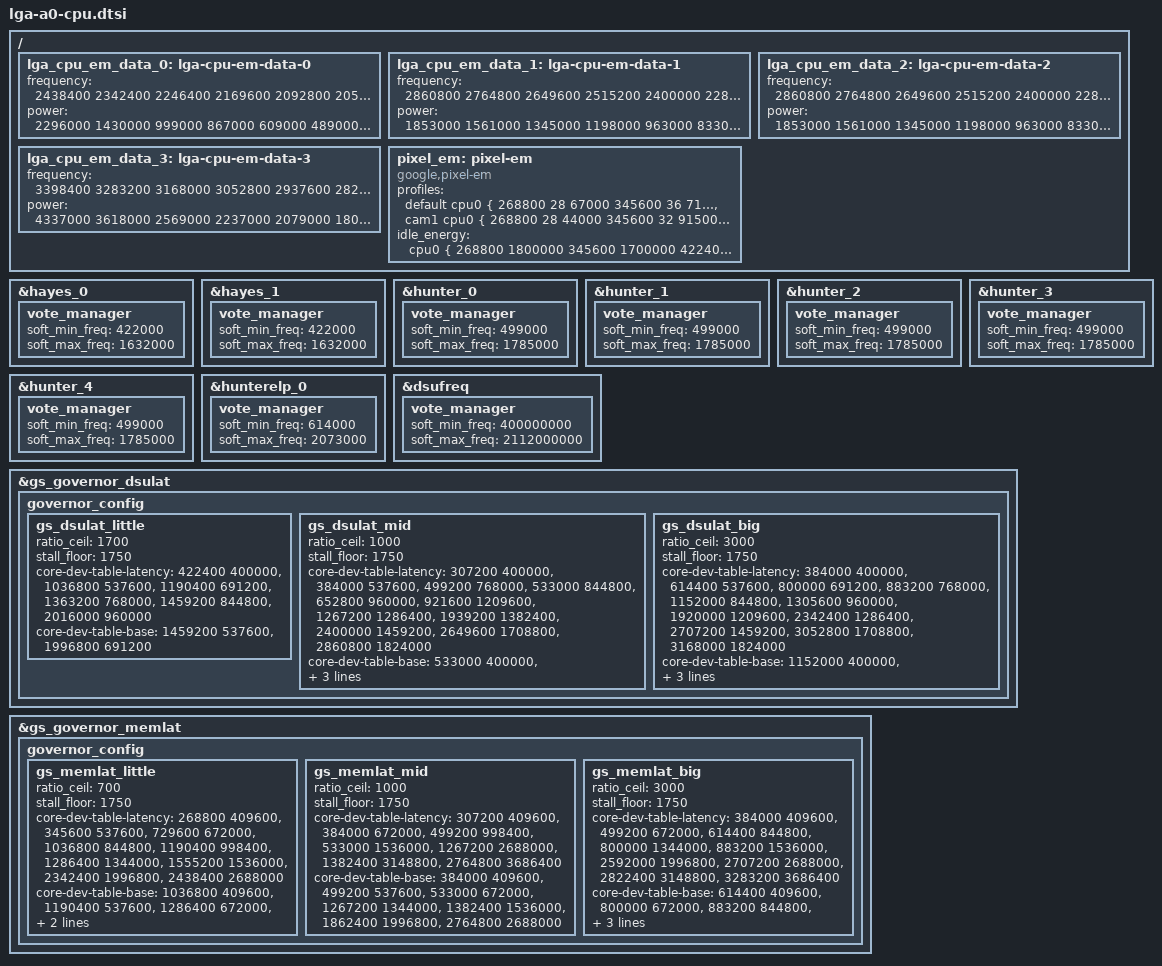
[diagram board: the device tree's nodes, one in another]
// SPDX-License-Identifier: GPL-2.0 OR BSD-3-Clause

&hayes_0 {
	vote_manager {
		soft_min_freq =  <422000>;
		soft_max_freq = <1632000>;
	};
};

&hayes_1 {
	vote_manager {
		soft_min_freq =  <422000>;
		soft_max_freq = <1632000>;
	};
};

&hunter_0 {
	vote_manager {
		soft_min_freq =  <499000>;
		soft_max_freq = <1785000>;
	};
};

&hunter_1 {
	vote_manager {
		soft_min_freq =  <499000>;
		soft_max_freq = <1785000>;
	};
};

&hunter_2 {
	vote_manager {
		soft_min_freq =  <499000>;
		soft_max_freq = <1785000>;
	};
};

&hunter_3 {
	vote_manager {
		soft_min_freq =  <499000>;
		soft_max_freq = <1785000>;
	};
};

&hunter_4 {
	vote_manager {
		soft_min_freq =  <499000>;
		soft_max_freq = <1785000>;
	};
};

&hunterelp_0 {
	vote_manager {
		soft_min_freq =  <614000>;
		soft_max_freq = <2073000>;
	};
};

&dsufreq {
	vote_manager {
		soft_min_freq = <400000000>;
		soft_max_freq = <2112000000>;
	};
};

&gs_governor_dsulat {
		governor_config {
			gs_dsulat_little {
				ratio_ceil = <1700>;
				stall_floor = <1750>;
				core-dev-table-latency =
				/* Little CPU    DSU */
				<  422400	400000 >,
				< 1036800	537600 >,
				< 1190400	691200 >,
				< 1363200	768000 >,
				< 1459200	844800 >,
				< 2016000	960000 >;

				core-dev-table-base =
				/* Little CPU    DSU */
				< 1459200	537600 >,
				< 1996800	691200 >;
			};
			gs_dsulat_mid {
				ratio_ceil = <1000>;
				stall_floor = <1750>;
				core-dev-table-latency =
				/* Mid CPU       DSU */
				<  307200	 400000 >,
				<  384000	 537600 >,
				<  499200	 768000 >,
				<  533000	 844800 >,
				<  652800	 960000 >,
				<  921600	1209600 >,
				< 1267200	1286400 >,
				< 1939200	1382400 >,
				< 2400000	1459200 >,
				< 2649600	1708800 >,
				< 2860800	1824000 >;

				core-dev-table-base =
				/* Mid CPU       DSU */
				<  533000	 400000 >,
				<  652800	 537600 >,
				< 1267200	 768000 >,
				< 2188800	 844800 >,
				< 2400000	 960000 >,
				< 2649600	1209600 >;

			};
			gs_dsulat_big {
				ratio_ceil = <3000>;
				stall_floor = <1750>;
				core-dev-table-latency =
				/* Big CPU       DSU */
				<  384000	 400000 >,
				<  614400	 537600 >,
				<  800000	 691200 >,
				<  883200	 768000 >,
				< 1152000	 844800 >,
				< 1305600	 960000 >,
				< 1920000	1209600 >,
				< 2342400	1286400 >,
				< 2707200	1459200 >,
				< 3052800	1708800 >,
				< 3168000	1824000 >;

				core-dev-table-base =
				/* Big CPU       DSU */
				< 1152000	 400000 >,
				< 1305600	 537600 >,
				< 1920000	 691200 >,
				< 2592000	 960000 >,
				< 3052800	1209600 >,
				< 3168000	1286400 >;
			};
		};
	};

&gs_governor_memlat {
		governor_config {
			gs_memlat_little {
				/* Todo (b/350517173): Update parameters and freq tables. */
				ratio_ceil = <700>;
				stall_floor = <1750>;
				core-dev-table-latency =
				/* LITTLE CPU	 GMC */
				< 268800	 409600 >,
				< 345600	 537600 >,
				< 729600	 672000 >,
				< 1036800	 844800 >,
				< 1190400	 998400 >,
				< 1286400	1344000 >,
				< 1555200	1536000 >,
				< 2342400	1996800 >,
				< 2438400	2688000 >;

				core-dev-table-base =
				/* LITTLE CPU    GMC */
				< 1036800	 409600 >,
				< 1190400	 537600 >,
				< 1286400	 672000 >,
				< 1555200	 844800 >,
				< 1776400        998400 >,
				< 2342400	1996800 >,
				< 2438400	2688000 >;
			};
			gs_memlat_mid {
				/* Todo (b/350517173): Update parameters and freq tables. */
				ratio_ceil = <1000>;
				stall_floor = <1750>;
				core-dev-table-latency =
				/* MID CPU	 GMC */
				< 307200	409600 >,
				< 384000	672000 >,
				< 499200	998400 >,
				< 533000	1536000 >,
				< 1267200	2688000 >,
				< 1382400	3148800 >,
				< 2764800	3686400 >;

				core-dev-table-base =
				/* MID CPU    	 GMC */
				< 384000	 409600 >,
				< 499200	 537600 >,
				< 533000	 672000 >,
				< 1267200	1344000 >,
				< 1382400	1536000 >,
				< 1862400       1996800 >,
				< 2764800	2688000 >;

			};
			gs_memlat_big {
				/* Todo (b/350517173): Update parameters and freq tables. */
				ratio_ceil = <3000>;
				stall_floor = <1750>;
				core-dev-table-latency =
				/* BIG CPU    	 GMC */
				< 384000	 409600 >,
				< 499200	 672000 >,
				< 614400	 844800 >,
				< 800000	1344000 >,
				< 883200	1536000 >,
				< 2592000	1996800 >,
				< 2707200	2688000 >,
				< 2822400	3148800 >,
				< 3283200	3686400 >;

				core-dev-table-base =
				/* BIG CPU    	GMC */
				< 614400	 409600 >,
				< 800000	 672000 >,
				< 883200	 844800 >,
				< 2208000        998400 >,
				< 2592000	1344000 >,
				< 2707200	1689600 >,
				< 2822400	1996800 >,
				< 3283200	2688000 >;
			};
		};
	};

/ {
	// the frequency/power list must in decreasing order
	lga_cpu_em_data_0: lga-cpu-em-data-0 {
		frequency = /bits/ 64 <2438400 2342400 2246400 2169600 2092800 2054400 2016000
					1996800 1881600 1766400 1632000 1555200 1459200 1363200
					1286400 1190400 1036800 883200 729600 533000 460800
					422400 345600 268800>;
		power = /bits/ 64 <2296000 1430000 999000 867000 609000 489000 403000 369000
					318000 279000 209000 198000 181000 164000 153000 134000
					124000 113000 99000 84000 77000 73000 71000 67000>;
	};

	lga_cpu_em_data_1: lga-cpu-em-data-1 {
		frequency =  /bits/ 64 <2860800 2764800 2649600 2515200 2400000 2284800 2188800
					2092800 2016000 1939200 1862400 1785600 1651200 1516800
					1382400 1267200 1075200 921600 729600 652800 533000
					499200 384000 307200>;
		power = /bits/ 64 <1853000 1561000 1345000 1198000 963000 833000 740000 647000
					585000 535000 480000 388000 334000 288000 247000 208000
					172000 146000 112000 98000 73000 70000 58000 50000>;
	};

	lga_cpu_em_data_2: lga-cpu-em-data-2 {
		frequency =  /bits/ 64 <2860800 2764800 2649600 2515200 2400000 2284800 2188800
					2092800 2016000 1939200 1862400 1785600 1651200 1516800
					1382400 1267200 1075200 921600 729600 652800 533000
					499200 384000 307200>;
		power = /bits/ 64 <1853000 1561000 1345000 1198000 963000 833000 740000 647000
					585000 535000 480000 388000 334000 288000 247000 208000
					172000 146000 112000 98000 73000 70000 58000 50000>;
	};

	lga_cpu_em_data_3: lga-cpu-em-data-3 {
		frequency =  /bits/ 64 <3398400 3283200 3168000 3052800 2937600 2822400 2707200
					2592000 2457600 2342400 2208000 2073600 1920000 1766400
					1593600 1420800 1305600 1152000 1036800 883200 800000
					614400 499200 384000>;
		power = /bits/ 64 <4337000 3618000 2569000 2237000 2079000 1807000 1563000 1361000
					1231000 1120000 982000 817000 752000 648000 539000 446000
					393000 349000 298000 261000 225000 166000 140000 115000>;
	};

	pixel_em: pixel-em {
		compatible = "google,pixel-em";
		profiles =
			"default
				cpu0 {
				268800 28 67000
				345600 36 71000
				422400 44 73000
				460800 48 77000
				533000 56 84000
				729600 77 99000
				883200 93 113000
				1036800 109 124000
				1190400 126 134000
				1286400 137 153000
				1363200 145 164000
				1459200 155 181000
				1555200 165 198000
				1632000 172 209000
				1766400 183 279000
				1881600 200 318000
				1996800 212 369000
				2016000 214 403000
				2054400 218 489000
				2092800 223 609000
				2169600 230 867000
				2246400 239 999000
				2342400 249 1430000
				2438400 258 2296000
				}
				cpu2 {
				307200 95 50000
				384000 119 58000
				499200 155 70000
				533000 165 73000
				652800 203 98000
				729600 227 112000
				921600 287 146000
				1075200 335 172000
				1267200 395 208000
				1382400 430 247000
				1516800 472 288000
				1651200 514 334000
				1785600 556 388000
				1862400 580 480000
				1939200 604 535000
				2016000 628 585000
				2092800 652 647000
				2188800 678 740000
				2284800 710 833000
				2400000 748 963000
				2515200 784 1198000
				2649600 825 1345000
				2764800 861 1561000
				2860800 891 1853000
				}
				cpu5 {
				307200 95 50000
				384000 119 58000
				499200 155 70000
				533000 165 73000
				652800 203 98000
				729600 227 112000
				921600 286 146000
				1075200 335 172000
				1267200 394 208000
				1382400 430 247000
				1516800 471 288000
				1651200 513 334000
				1785600 555 388000
				1862400 579 480000
				1939200 603 535000
				2016000 627 585000
				2092800 651 647000
				2188800 678 740000
				2284800 711 833000
				2400000 748 963000
				2515200 783 1198000
				2649600 821 1345000
				2764800 861 1561000
				2860800 892 1853000
				}
				cpu7 {
				384000 142 115000
				499200 182 140000
				614400 227 166000
				800000 281 225000
				883200 325 261000
				1036800 359 298000
				1152000 408 349000
				1305600 455 393000
				1420800 511 446000
				1593600 584 539000
				1766400 657 648000
				1920000 722 752000
				2073600 766 817000
				2208000 811 982000
				2342400 878 1120000
				2457600 929 1231000
				2592000 930 1361000
				2707200 965 1563000
				2822400 1019 1807000
				2937600 1020 2079000
				3052800 1021 2237000
				3168000 1022 2569000
				3283200 1023 3618000
				3398400 1024 4337000
				}
			",
			"cam1
				cpu0 {
				268800 28 44000
				345600 32 91500
				422400 37 139000
				460800 39 162750
				533000 44 207404
				729600 56 329000
				883200 66 424000
				1036800 94 687901
				1190400 123 951802
				1286400 141 1116740
				1363200 156 1248691
				1459200 174 1413629
				1555200 192 1578567
				1632000 206 1710518
				1766400 231 1941432
				1881600 253 2139358
				1996800 275 2337283
				2016000 278 2370271
				2054400 285 2436246
				2092800 293 2502222
				2169600 307 2634172
				2246400 321 2766123
				2342400 339 2931061
				2438400 358 3096000
				}
				cpu2 {
				307200 95 50000
				384000 109 53200
				499200 130 58000
				533000 136 59408
				652800 158 64400
				729600 172 67600
				921600 206 75600
				1075200 235 82000
				1267200 278 112434
				1382400 304 130695
				1516800 335 152000
				1651200 363 249600
				1785600 392 347200
				1862400 408 402971
				1939200 424 458742
				2016000 441 514514
				2092800 457 570285
				2188800 478 640000
				2284800 508 813285
				2400000 544 1021228
				2515200 581 1229171
				2649600 624 1471771
				2764800 660 1679714
				2860800 691 1853000
				}
				cpu5 {
				307200 95 50000
				384000 109 53200
				499200 130 58000
				533000 136 59408
				652800 158 64400
				729600 172 67600
				921600 206 75600
				1075200 235 82000
				1267200 278 112434
				1382400 304 130695
				1516800 335 152000
				1651200 363 249600
				1785600 392 347200
				1862400 408 402971
				1939200 424 458742
				2016000 441 514514
				2092800 457 570285
				2188800 478 640000
				2284800 508 813285
				2400000 544 1021228
				2515200 581 1229171
				2649600 624 1471771
				2764800 660 1679714
				2860800 691 1853000
				}
				cpu7 {
				384000 142 125000
				499200 166 183941
				614400 190 242882
				800000 228 337843
				883200 245 380411
				1036800 278 459000
				1152000 330 539950
				1305600 400 647885
				1420800 452 728836
				1593600 531 850262
				1766400 610 971688
				1920000 679 1079622
				2073600 749 1187557
				2208000 811 1282000
				2342400 828 1433931
				2457600 843 1564159
				2592000 861 1716090
				2707200 876 1846318
				2822400 891 1976545
				2937600 906 2106772
				3052800 921 2237000
				3168000 955 2937000
				3283200 989 3636999
				3398400 1024 4337000
				}
			";
			idle_energy =
			"
				cpu0 {
				268800 1800000
				345600 1700000
				422400 1500000
				460800 2400000
				533000 1500000
				729600 1600000
				883200 1600000
				1036800 3400000
				1190400 1800000
				1286400 1900000
				1363200 1900000
				1459200 2400000
				1555200 2200000
				1632000 2500000
				1766400 3000000
				1881600 2700000
				1996800 3400000
				2016000 3200000
				2054400 3600000
				2092800 3800000
				2169600 5100000
				2246400 5700000
				2342400 6000000
				2438400 6500000
				}
				cpu 2 {
				307200 400000
				384000 400000
				499200 400000
				533000 400000
				652800 500000
				729600 400000
				921600 500000
				1075200 600000
				1267200 700000
				1382400 800000
				1516800 800000
				1651200 1000000
				1785600 1200000
				1862400 1000000
				1939200 1300000
				2016000 1300000
				2092800 1200000
				2188800 1700000
				2284800 1600000
				2400000 1600000
				2515200 2200000
				2649600 2200000
				2764800 2200000
				2860800 2700000
				}
				cpu 5 {
				307200 800000
				384000 800000
				499200 800000
				533000 800000
				652800 900000
				729600 800000
				921600 900000
				1075200 1100000
				1267200 1000000
				1382400 1100000
				1516800 1100000
				1651200 1100000
				1785600 1400000
				1862400 1200000
				1939200 1400000
				2016000 1500000
				2092800 1600000
				2188800 1900000
				2284800 2200000
				2400000 2500000
				2515200 3000000
				2649600 2900000
				2764800 3900000
				2860800 4000000
				}
				cpu7 {
				384000 2900000
				499200 2700000
				614400 3200000
				800000 3400000
				883200 3200000
				1036800 3600000
				1152000 3500000
				1305600 4300000
				1420800 4500000
				1593600 4700000
				1766400 5600000
				1920000 6500000
				2073600 7200000
				2208000 7000000
				2342400 8700000
				2457600 8600000
				2592000 10600000
				2707200 12000000
				2822400 12000000
				2937600 11500000
				3052800 12000000
				3168000 16100000
				3283200 18700000
				3398400 20400000
				}
			";
	};

};
